# WKUP_CTRL_MMR0_CFG0 register map
Vendor: Texas Instruments
Peripheral module from a debugger description file (folder J7VCL).
Registers are 32-bit, access per field, reset 0x0 unless marked. A register's access mark holds for its fields unless they carry their own. Offsets are as the file gives them; lines under a group give offsets from that group; [hi:lo] are bit positions; {n}, {i} and the like mark numbered series; 'fields as' and 'values as' point back to an identical list; <NAME> marks a mode.

## WKUP_CTRL_MMR0_CFG0 (part 1 of 2)
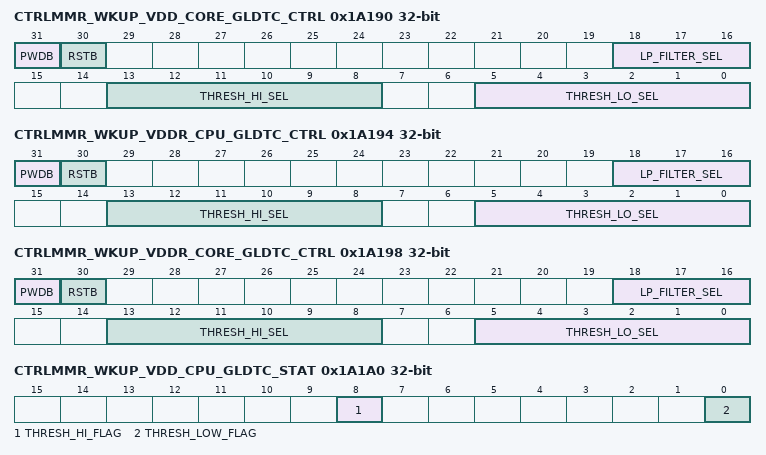
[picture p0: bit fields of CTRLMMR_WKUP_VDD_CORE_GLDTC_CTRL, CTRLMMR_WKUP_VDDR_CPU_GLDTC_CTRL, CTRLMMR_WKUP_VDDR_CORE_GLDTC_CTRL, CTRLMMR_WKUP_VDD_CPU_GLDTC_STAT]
0x1A190 CTRLMMR_WKUP_VDD_CORE_GLDTC_CTRL (reset mask 0xFFF8C0C0)
  [31] PWDB rw — Power down - active low.
  [30] RSTB rw — Reset - active low. To ensure proper operation, rstb must be not be de-asserted for at least 100 ns after power-up (pwdb de-asserted). Additionally, rstb must be toggled low at least 200 ns after any change in threshold or low-pass filter settings to prevent abnormal trigger events.
  [18:16] LP_FILTER_SEL rw — Selects the glitch detect low-pass filter bandwidth 0h - 150 kHz 1h - 125 kHz 2h - 100 kHz 3h - 80 kHz 4h - 60 kHz 5h - 45 kHz 6h - 30 kHz 7h - 15 kHz
  [13:8] THRESH_HI_SEL rw — Selects the high voltage glitch threshold as a percentage of the monitored voltage 0h - 93.5% of VDD 1h - 94.0% of VDD 2h - 94.5% of VDD 3h - 95.0% of VDD 4h - 95.5% of VDD 5h - 96.0% of VDD 6h - 96.5% of VDD 7h - 97.0% of VDD 8h - 97.5% of VDD 9h - 98.0% of VDD Ah - 98.5% of VDD Bh - 99.0% of VDD Ch - 99.5% of VDD Dh - 100.0% of VDD Eh - 100.5% of VDD Fh - 101.0% of VDD 10h - 101.5% of VDD 11h - 102.0% of VDD 12h - 102.5% of VDD 13h - 103.0% of VDD 14h - 103.5% of VDD 15h - 104.0% of VDD 16h - 104.5% of VDD 17h - 105.0% of VDD 18h - 105.5% of VDD 19h - 106.0% of VDD 1Ah - 106.5% of VDD 1Bh - 107.0% of VDD 1Ch - 107.5% of VDD 1Dh - 108.0% of VDD 1Eh - 108.5% of VDD 1Fh - 109.0% of VDD 20h - 109.5% of VDD 21h - 110.0% of VDD 22h - 111.0% of VDD 23h - 112.0% of VDD 24h - 113.0% of VDD 25h - 114.0% of VDD 26h - 115.0% of VDD 27h - 116.0% of VDD 28h - 117.0% of VDD 29h - 118.0% of VDD 2Ah - 119.0% of VDD 2Bh - 120.0% of VDD 2Ch - 121.0% of VDD 2Dh - 122.0% of VDD 2Eh - 123.0% of VDD 2Fh - 124.0% of VDD 30h - 125.0% of VDD 31h - 126.0% of VDD 32h - 127.0% of VDD 33h - 128.0% of VDD 34h - 129.0% of VDD 35h - 130.0% of VDD 36h - 131.0% of VDD 37h - 132.0% of VDD 38h - 133.0% of VDD 39h - 134.0% of VDD 3Ah - 135.0% of VDD 3Bh - 136.0% of VDD 3Ch - 137.0% of VDD 3Dh - 138.0% of VDD 3Eh - 139.0% of VDD 3Fh - 140.0% of VDD
  [5:0] THRESH_LO_SEL rw — Selects the low voltage glitch threshold as a percentage of the monitored voltage 0h - 106.5% of VDD 1h - 106.0% of VDD 2h - 105.5% of VDD 3h - 105.0% of VDD 4h - 104.5% of VDD 5h - 104.0% of VDD 6h - 103.5% of VDD 7h - 103.0% of VDD 8h - 102.5% of VDD 9h - 102.0% of VDD Ah - 101.5% of VDD Bh - 101.0% of VDD Ch - 100.5% of VDD Dh - 100.0% of VDD Eh - 99.5% of VDD Fh - 99.0% of VDD 10h - 98.5% of VDD 11h - 98.0% of VDD 12h - 97.5% of VDD 13h - 97.0% of VDD 14h - 96.5% of VDD 15h - 96.0% of VDD 16h - 95.5% of VDD 17h - 95.0% of VDD 18h - 94.5% of VDD 19h - 94.0% of VDD 1Ah - 93.5% of VDD 1Bh - 93.0% of VDD 1Ch - 92.5% of VDD 1Dh - 92.0% of VDD 1Eh - 91.5% of VDD 1Fh - 91.0% of VDD 20h - 90.5% of VDD 21h - 90.0% of VDD 22h - 89.0% of VDD 23h - 88.0% of VDD 24h - 87.0% of VDD 25h - 86.0% of VDD 26h - 85.0% of VDD 27h - 84.0% of VDD 28h - 83.0% of VDD 29h - 82.0% of VDD 2Ah - 81.0% of VDD 2Bh - 80.0% of VDD 2Ch - 79.0% of VDD 2Dh - 78.0% of VDD 2Eh - 77.0% of VDD 2Fh - 76.0% of VDD 30h - 75.0% of VDD 31h - 74.0% of VDD 32h - 73.0% of VDD 33h - 72.0% of VDD 34h - 71.0% of VDD 35h - 70.0% of VDD 36h - 69.0% of VDD 37h - 68.0% of VDD 38h - 67.0% of VDD 39h - 66.0% of VDD 3Ah - 65.0% of VDD 3Bh - 64.0% of VDD 3Ch - 63.0% of VDD 3Dh - 62.0% of VDD 3Eh - 61.0% of VDD 3Fh - 60.0% of VDD
0x1A194 CTRLMMR_WKUP_VDDR_CPU_GLDTC_CTRL (reset mask 0xFFF8C0C0)
  fields as CTRLMMR_WKUP_VDD_CORE_GLDTC_CTRL
0x1A198 CTRLMMR_WKUP_VDDR_CORE_GLDTC_CTRL (reset mask 0xFFF8C0C0)
  fields as CTRLMMR_WKUP_VDD_CORE_GLDTC_CTRL
0x1A1A0 CTRLMMR_WKUP_VDD_CPU_GLDTC_STAT ro (reset mask 0xFFFFFEFE)
  [8] THRESH_HI_FLAG — High voltage flag. This flag is cleared by clearing the VDD_CPU_GLDTC_CTRL_rstb bit.
  [0] THRESH_LOW_FLAG — Low voltage flag. This flag is cleared by clearing the VDD_CPU_GLDTC_CTRL_rstb bit.
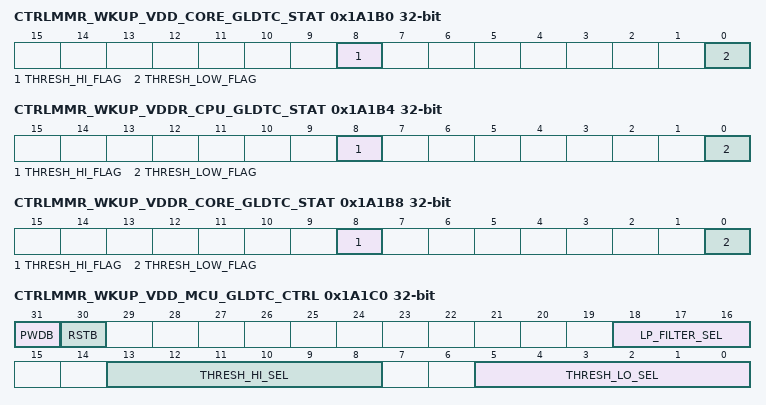
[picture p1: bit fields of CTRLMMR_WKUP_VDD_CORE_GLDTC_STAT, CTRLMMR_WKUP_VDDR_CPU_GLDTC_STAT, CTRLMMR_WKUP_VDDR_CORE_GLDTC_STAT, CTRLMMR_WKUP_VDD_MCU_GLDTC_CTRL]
0x1A1B0 CTRLMMR_WKUP_VDD_CORE_GLDTC_STAT ro (reset mask 0xFFFFFEFE)
  [8] THRESH_HI_FLAG — High voltage flag. This flag is cleared by clearing the VDD_CORE_GLDTC_CTRL_rstb bit.
  [0] THRESH_LOW_FLAG — Low voltage flag. This flag is cleared by clearing the VDD_CORE_GLDTC_CTRL_rstb bit.
0x1A1B4 CTRLMMR_WKUP_VDDR_CPU_GLDTC_STAT ro (reset mask 0xFFFFFEFE)
  [8] THRESH_HI_FLAG — High voltage flag. This flag is cleared by clearing the VDDR_CPU_GLDTC_CTRL_rstb bit.
  [0] THRESH_LOW_FLAG — Low voltage flag. This flag is cleared by clearing the VDDR_CPU_GLDTC_CTRL_rstb bit.
0x1A1B8 CTRLMMR_WKUP_VDDR_CORE_GLDTC_STAT ro (reset mask 0xFFFFFEFE)
  [8] THRESH_HI_FLAG — High voltage flag. This flag is cleared by clearing the VDDR_CORE_GLDTC_CTRL_rstb bit.
  [0] THRESH_LOW_FLAG — Low voltage flag. This flag is cleared by clearing the VDDR_CORE_GLDTC_CTRL_rstb bit.
0x1A1C0 CTRLMMR_WKUP_VDD_MCU_GLDTC_CTRL (reset mask 0xFFF8C0C0)
  fields as CTRLMMR_WKUP_VDD_CORE_GLDTC_CTRL
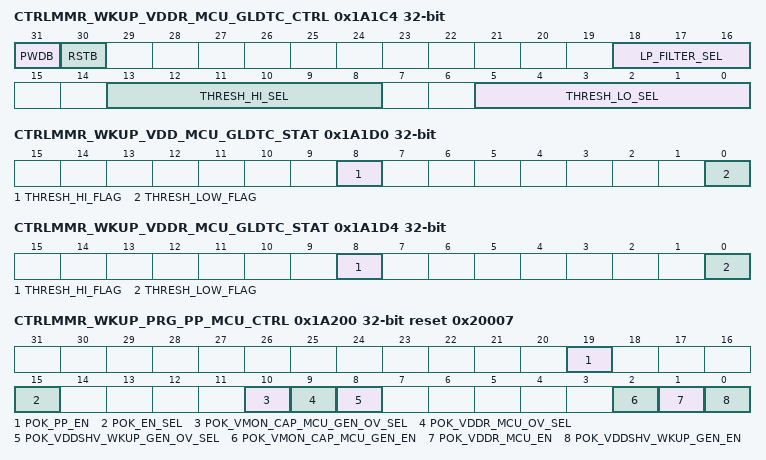
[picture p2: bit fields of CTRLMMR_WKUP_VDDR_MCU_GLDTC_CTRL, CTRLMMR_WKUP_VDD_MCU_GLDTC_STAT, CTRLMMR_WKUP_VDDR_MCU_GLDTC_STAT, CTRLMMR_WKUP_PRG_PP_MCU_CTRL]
0x1A1C4 CTRLMMR_WKUP_VDDR_MCU_GLDTC_CTRL (reset mask 0xFFF8C0C0)
  fields as CTRLMMR_WKUP_VDD_CORE_GLDTC_CTRL
0x1A1D0 CTRLMMR_WKUP_VDD_MCU_GLDTC_STAT ro (reset mask 0xFFFFFEFE)
  [8] THRESH_HI_FLAG — High voltage flag. This flag is cleared by clearing the VDD_MCU_GLDTC_CTRL_rstb bit.
  [0] THRESH_LOW_FLAG — Low voltage flag. This flag is cleared by clearing the VDD_MCU_GLDTC_CTRL_rstb bit.
0x1A1D4 CTRLMMR_WKUP_VDDR_MCU_GLDTC_STAT ro (reset mask 0xFFFFFEFE)
  [8] THRESH_HI_FLAG — High voltage flag. This flag is cleared by clearing the VDDR_MCU_GLDTC_CTRL_rstb bit.
  [0] THRESH_LOW_FLAG — Low voltage flag. This flag is cleared by clearing the VDDR_MCU_GLDTC_CTRL_rstb bit.
0x1A200 CTRLMMR_WKUP_PRG_PP_MCU_CTRL reset 0x20007
  [19] POK_PP_EN rw — POK ping-pong enable. When set, enables automatic switching between undervoltage and overvoltage detection on VDDSHV_WKUP_GENERAL, VDDR_MCU and VMON_CAP_MCU_GENERAL POKs. This bit has no effect if the POK's ov_sel bit = 1.
  [15] POK_EN_SEL rw — Select POK enable source
  [10] POK_VMON_CAP_MCU_GEN_OV_SEL rw — Force VMON_CAP_MCU_GENERAL POK overvoltage detection. If this bit is 0 and pok_pp_en bit is also 0 then only undervoltage detection is enabled.
  [9] POK_VDDR_MCU_OV_SEL rw — Force VDDR_MCU POK overvoltage detection. If this bit is 0 and pok_pp_en bit is also 0 then only undervoltage detection is enabled.
  [8] POK_VDDSHV_WKUP_GEN_OV_SEL rw — Force VDDSHV_WKUP_GENERAL POK overvoltage detection. If this bit is 0 and pok_pp_en bit is also 0 then only undervoltage detection is enabled.
  [2] POK_VMON_CAP_MCU_GEN_EN rw — Enable VMON_CAP_MCU_GENERAL POK detection
  [1] POK_VDDR_MCU_EN rw — Enable VDDR_MCU POK detection
  [0] POK_VDDSHV_WKUP_GEN_EN rw — Enable VDDSHV_WKUP_GENERAL POK detection
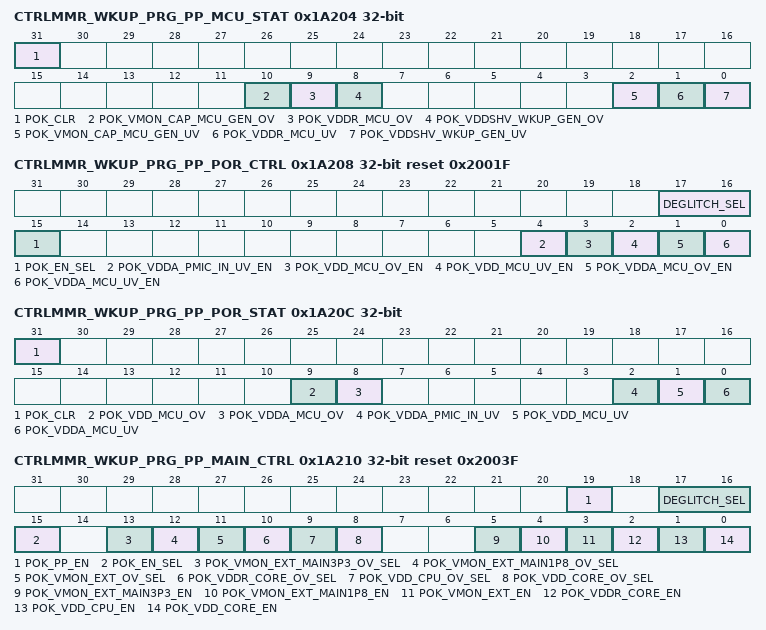
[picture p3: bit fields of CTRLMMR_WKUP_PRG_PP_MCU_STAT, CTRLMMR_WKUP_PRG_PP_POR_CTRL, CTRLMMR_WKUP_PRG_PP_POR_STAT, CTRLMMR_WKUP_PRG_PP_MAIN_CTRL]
0x1A204 CTRLMMR_WKUP_PRG_PP_MCU_STAT (reset mask 0xFFFFF8F8)
  [31] POK_CLR rw — When set, resets pgood sticky bits for VDDSHV_WKUP_GENERAL, VDDR_MCU, and VMON_CAP_MCU_GENERAL voltage POK detection.
  [10] POK_VMON_CAP_MCU_GEN_OV ro — VMON_CAP_MCU_GENERAL overvoltage POK
  [9] POK_VDDR_MCU_OV ro — VDDR_MCU overvoltage POK
  [8] POK_VDDSHV_WKUP_GEN_OV ro — VDDSHV_WKUP_GENERAL overvoltage POK
  [2] POK_VMON_CAP_MCU_GEN_UV ro — VMON_CAP_MCU_GENERAL undervoltage POK
  [1] POK_VDDR_MCU_UV ro — VDDR_MCU undervoltage POK
  [0] POK_VDDSHV_WKUP_GEN_UV ro — VDDSHV_WKUP_GENERAL undervoltage POK
0x1A208 CTRLMMR_WKUP_PRG_PP_POR_CTRL reset 0x2001F
  [17:16] DEGLITCH_SEL rw — Deglitch period for PRG_PP_POR POKs 0h - 5 us 1h - 10 us 2h - 15 us 3h - 20 us
  [15] POK_EN_SEL rw — Select POK enable source
  [4] POK_VDDA_PMIC_IN_UV_EN rw — Enable VDDA_PMIC_IN undervoltage POK detection
  [3] POK_VDD_MCU_OV_EN rw — Enable VDD_MCU overvoltage POK detection
  [2] POK_VDD_MCU_UV_EN rw — Enable VDD_MCU undervoltage POK detection
  [1] POK_VDDA_MCU_OV_EN rw — Enable 1.8V VDDA_MCU overvoltage POK detection
  [0] POK_VDDA_MCU_UV_EN rw — Enable 1.8V VDDA_MCU undervoltage POK detection
0x1A20C CTRLMMR_WKUP_PRG_PP_POR_STAT (reset mask 0xFFFFFCF8)
  [31] POK_CLR rw — When set, resets pgood sticky bits for VDDA_MCU, VDD_MCU, and VDDA_PMIC_IN voltage POK detection.
  [9] POK_VDD_MCU_OV ro — VDD_MCU overvoltage POK detection
  [8] POK_VDDA_MCU_OV ro — 1.8V VDDA_MCU overvoltage POK detection
  [2] POK_VDDA_PMIC_IN_UV ro — VDDA_PMIC_IN undervoltage POK detection
  [1] POK_VDD_MCU_UV ro — VDD_MCU undervoltage POK detection
  [0] POK_VDDA_MCU_UV ro — 1.8V VDDA_MCU undervoltage POK detection
0x1A210 CTRLMMR_WKUP_PRG_PP_MAIN_CTRL reset 0x2003F
  [19] POK_PP_EN rw — POK ping-pong enable. When set, enables automatic switching between undervoltage and overvoltage detection on VDD_CORE, VDD_CPU, VDDR_CORE, VMON_EXT, VMON_EXT_MAIN1P8 and VMON_EXT_MAIN3P3. This bit has no effect if the POK's ov_sel bit = 1.
  [17:16] DEGLITCH_SEL rw — Deglitch period for PRG_PP_MAIN POKs 0h - 5 us 1h - 10 us 2h - 15 us 3h - 20 us
  [15] POK_EN_SEL rw — Select POK enable source
  [13] POK_VMON_EXT_MAIN3P3_OV_SEL rw — Force VMON_EXT_MAIN 3.3V POK overvoltage detection. If this bit is 0 and pok_pp_en bit is also 0 then only undervoltage detection is enabled.
  [12] POK_VMON_EXT_MAIN1P8_OV_SEL rw — Force VMON_EXT_MAIN 1.8V POK overvoltage detection. If this bit is 0 and pok_pp_en bit is also 0 then only undervoltage detection is enabled.
  [11] POK_VMON_EXT_OV_SEL rw — Force VMON_EXT POK overvoltage detection. If this bit is 0 and pok_pp_en bit is also 0 then only undervoltage detection is enabled.
  [10] POK_VDDR_CORE_OV_SEL rw — Force VDDR_CORE POK overvoltage detection. If this bit is 0 and pok_pp_en bit is also 0 then only undervoltage detection is enabled.
  [9] POK_VDD_CPU_OV_SEL rw — Force VDD_CPU POK overvoltage detection. If this bit is 0 and pok_pp_en bit is also 0 then only undervoltage detection is enabled.
  [8] POK_VDD_CORE_OV_SEL rw — Force VDD_CORE POK overvoltage detection. If this bit is 0 and pok_pp_en bit is also 0 then only undervoltage detection is enabled.
  [5] POK_VMON_EXT_MAIN3P3_EN rw — Enable VMON_EXT_MAIN 3.3V POK detection
  [4] POK_VMON_EXT_MAIN1P8_EN rw — Enable VMON_EXT_MAIN 1.8V POK detection
  [3] POK_VMON_EXT_EN rw — Enable VMON_EXT POK detection
  [2] POK_VDDR_CORE_EN rw — Enable VDDR_CORE POK detection
  [1] POK_VDD_CPU_EN rw — Enable VDD_CPU POK detection
  [0] POK_VDD_CORE_EN rw — Enable VDD_CORE POK detection
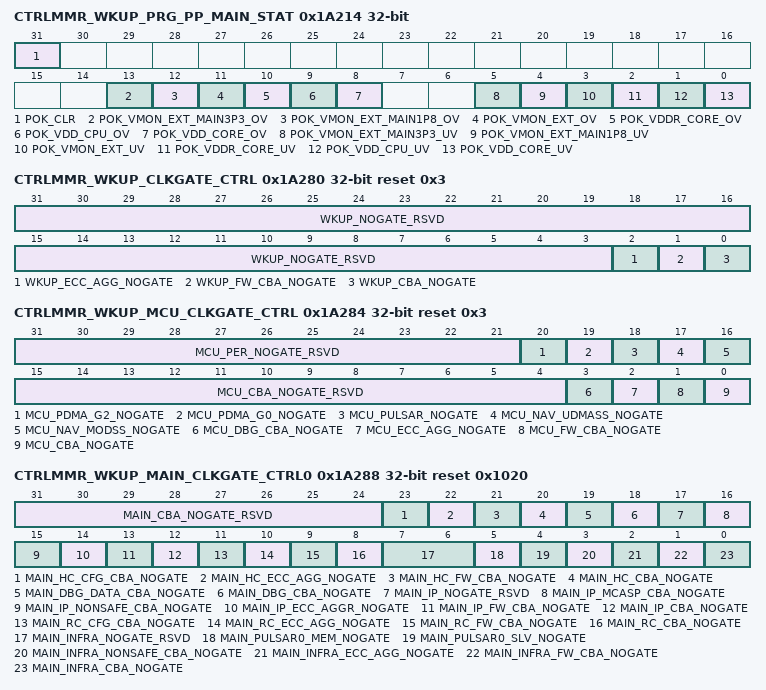
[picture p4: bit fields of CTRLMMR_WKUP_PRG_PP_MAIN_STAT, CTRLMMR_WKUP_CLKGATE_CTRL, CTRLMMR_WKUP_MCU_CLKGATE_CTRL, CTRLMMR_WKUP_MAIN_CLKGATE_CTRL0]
0x1A214 CTRLMMR_WKUP_PRG_PP_MAIN_STAT (reset mask 0xFFFFC0C0)
  [31] POK_CLR rw — When set, resets pgood sticky bits for V DD_CORE, VDD_CPU, VDDR_CORE, VMON_EXT, VMON_EXT_MAIN1P8, and VMON_EXT_MAIN3P3 voltage POK detection.
  [13] POK_VMON_EXT_MAIN3P3_OV ro — VMON_EXT_MAIN 3.3V overvoltage POK
  [12] POK_VMON_EXT_MAIN1P8_OV ro — VMON_EXT_MAIN 1.8V overvoltage POK
  [11] POK_VMON_EXT_OV ro — VMON_EXT overvoltage POK
  [10] POK_VDDR_CORE_OV ro — VDDR_CORE overvoltage POK
  [9] POK_VDD_CPU_OV ro — VDD_CPU overvoltage POK
  [8] POK_VDD_CORE_OV ro — VDD_CORE overvoltage POK
  [5] POK_VMON_EXT_MAIN3P3_UV ro — VMON_EXT_MAIN 3.3V undervoltage POK
  [4] POK_VMON_EXT_MAIN1P8_UV ro — VMON_EXT_MAIN 1.8V undervoltage POK
  [3] POK_VMON_EXT_UV ro — VMON_EXT undervoltage POK
  [2] POK_VDDR_CORE_UV ro — VDDR_CORE undervoltage POK
  [1] POK_VDD_CPU_UV ro — VDD_CPU undervoltage POK
  [0] POK_VDD_CORE_UV ro — VDD_CORE undervoltage POK
0x1A280 CTRLMMR_WKUP_CLKGATE_CTRL rw reset 0x3 (reset mask 0x3)
  [31:3] WKUP_NOGATE_RSVD — WKUP reserved clock gate disable. These bits should remain unchanged (written only with their default value) to maintain compatibility with future devices.
  [2] WKUP_ECC_AGG_NOGATE — WKUP ECC Aggregator clock gate disable
  [1] WKUP_FW_CBA_NOGATE — WKUP domain Firewall bus (wkup_fw_cbass) clock gate disable
  [0] WKUP_CBA_NOGATE — WKUP domain Data bus (wkup_cbass) clock gate disable
0x1A284 CTRLMMR_WKUP_MCU_CLKGATE_CTRL rw reset 0x3 (reset mask 0x3)
  [31:21] MCU_PER_NOGATE_RSVD — MCU reserved clock gate disable. These bits should remain unchanged (written only with their default value) to maintain compatibility with future devices.
  [20] MCU_PDMA_G2_NOGATE — MCU domain MCAN1/USART0 PDMA clock gate disable.
  [19] MCU_PDMA_G0_NOGATE — MCU domain MCAN0/SPI0 PDMA clock gate disable.
  [18] MCU_PULSAR_NOGATE — MCU domain Pulsar clock gate disable.
  [17] MCU_NAV_UDMASS_NOGATE — MCU NavSS UDMA interface clock gate disable.
  [16] MCU_NAV_MODSS_NOGATE — MCU NavSS MODSS interface clock gate disable.
  [15:4] MCU_CBA_NOGATE_RSVD — MCU reserved clock gate disable. These bits should remain unchanged (written only with their default value) to maintain compatibility with future devices.
  [3] MCU_DBG_CBA_NOGATE — MCU domain Debug bus (mcu_dbg_cbass) clock gate disable.
  [2] MCU_ECC_AGG_NOGATE — MCU ECC Aggregator clock gate disable
  [1] MCU_FW_CBA_NOGATE — MCU domain Firewall bus (mcu_fw_cbass) clock gate disable.
  [0] MCU_CBA_NOGATE — MCU domain Data bus (mcu_cbass) clock gate disable.
0x1A288 CTRLMMR_WKUP_MAIN_CLKGATE_CTRL0 rw reset 0x1020 (reset mask 0x1020)
  [31:24] MAIN_CBA_NOGATE_RSVD — MAIN CBA reserved clock gate disable. These bits should remain unchanged (written only with their default value) to maintain compatibility with future devices.
  [23] MAIN_HC_CFG_CBA_NOGATE — MAIN domain HC Configuration bus (hc_cfg_cbass_0) clock gate disable.
  [22] MAIN_HC_ECC_AGG_NOGATE — MAIN domain HC ECC aggregator (nogate) clock gate disable.
  [21] MAIN_HC_FW_CBA_NOGATE — MAIN domain HC Firewall bus (main_hc2_fw_cbass_0) clock gate disable.
  [20] MAIN_HC_CBA_NOGATE — MAIN domain HC Data bus (hc2_cbass_0) clock gate disable.
  [19] MAIN_DBG_DATA_CBA_NOGATE — MAIN domain Debug Data bus (debug_cbass) clock gate disable.
  [18] MAIN_DBG_CBA_NOGATE — MAIN domain Debug bus (debug_cbass_wrap_main_0) clock gate disable.
  [17] MAIN_IP_NOGATE_RSVD — MAIN Interface Peripheral reserved clock gate disable. These bits should remain unchanged (written only with their default value) to maintain compatibility with future devices.
  [16] MAIN_IP_MCASP_CBA_NOGATE — MAIN domain Interface Peripheral McASP IP bus (ipphy_mcasp_g0) clock gate disable.
  [15] MAIN_IP_NONSAFE_CBA_NOGATE — MAIN domain Interface Peripheral nonsafety IP bus (ipphy_cbass_0) clock gate disable.
  [14] MAIN_IP_ECC_AGGR_NOGATE — MAIN domain Interface Peripheral ECC aggregator (main_spi0_g0_main_0_ecc_aggr_main_0) clock gate disable.
  [13] MAIN_IP_FW_CBA_NOGATE — MAIN domain Interface Peripheral Firewall bus (ipphy_cbass_main_fw_cbass) clock gate disable.
  [12] MAIN_IP_CBA_NOGATE — MAIN domain Interface Peripheral bus (ipphy_safe_cbass_0) clock gate disable.
  [11] MAIN_RC_CFG_CBA_NOGATE — MAIN domain RC Configuration bus (rc_cfg_cbass_0) clock gate disable.
  [10] MAIN_RC_ECC_AGG_NOGATE — MAIN domain RC ECC aggregator (main_rc_ecc_aggr_main_0) clock gate disable.
  [9] MAIN_RC_FW_CBA_NOGATE — MAIN domain RC Firewall bus (rc_cbass_main_fw_cbass) clock gate disable.
  [8] MAIN_RC_CBA_NOGATE — MAIN domain RC Data bus (rc_cbass_0) clock gate disable.
  [7:6] MAIN_INFRA_NOGATE_RSVD — MAIN Infrastructure reserved clock gate disable. These bits should remain unchanged (written only with their default value) to maintain compatibility with future devices.
  [5] MAIN_PULSAR0_MEM_NOGATE — MAIN domain Pulsar memory bus (pulsar0_mem_cbass) clock gate disable.
  [4] MAIN_PULSAR0_SLV_NOGATE — MAIN domain Pulsar slave bus (pulsar0_slv_cbass) clock gate disable.
  [3] MAIN_INFRA_NONSAFE_CBA_NOGATE — MAIN domain Infrastructure non-safety IP bus (main_infra_non_safe_cbass) clock gate disable.
  [2] MAIN_INFRA_ECC_AGG_NOGATE — MAIN domain Infrastructure ECC aggregator (main_infra_ecc_aggr) clock gate disable.
  [1] MAIN_INFRA_FW_CBA_NOGATE — MAIN domain Infrastructure Firewall bus (main_infra_fw_cbass) clock gate disable.
  [0] MAIN_INFRA_CBA_NOGATE — MAIN domain Infrastructure bus (main_infra_cbass) clock gate disable.
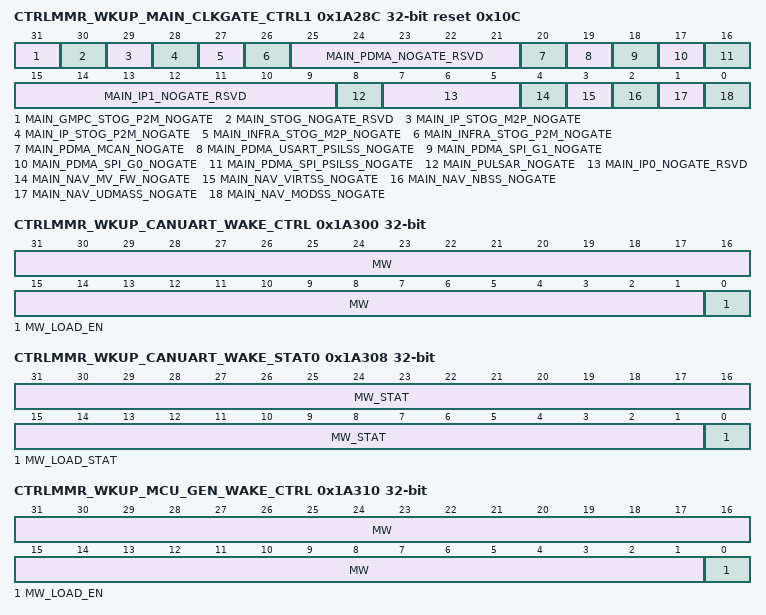
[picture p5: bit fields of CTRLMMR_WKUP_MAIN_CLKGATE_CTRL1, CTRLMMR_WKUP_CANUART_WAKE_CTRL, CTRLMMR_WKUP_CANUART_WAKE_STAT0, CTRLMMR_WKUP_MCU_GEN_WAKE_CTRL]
0x1A28C CTRLMMR_WKUP_MAIN_CLKGATE_CTRL1 rw reset 0x10C (reset mask 0x10C)
  [31] MAIN_GMPC_STOG_P2M_NOGATE — MAIN domain GPMC Slave Timeout Gasket output (rc_to_gpmc_stog_p2m_pwr_dis) clock gate disable.
  [30] MAIN_STOG_NOGATE_RSVD — MAIN STOG clock gate disable. These bits should remain unchanged (written only with their default value) to maintain compatibility with future devices.
  [29] MAIN_IP_STOG_M2P_NOGATE — MAIN domain IP Slave Timeout Gasket output (ipphy_to_ipphy_stog_p2m_pwr_dis) clock gate disable.
  [28] MAIN_IP_STOG_P2M_NOGATE — MAIN domain IP Slave Timeout Gasket input (ipphy_to_ipphy_stog_p2m_pwr_dis) clock gate disable.
  [27] MAIN_INFRA_STOG_M2P_NOGATE — MAIN domain Infrastructure Slave Timeout Gasket output (main_infra_0_mst_stog_p2m_pwr_dis) clock gate disable.
  [26] MAIN_INFRA_STOG_P2M_NOGATE — MAIN domain Infrastructure Slave Timeout Gasket input (main_infra_0_mst_stog_p2m_pwr_dis) clock gate disable.
  [25:21] MAIN_PDMA_NOGATE_RSVD — MAIN PDMA clock gate disable. These bits should remain unchanged (written only with their default value) to maintain compatibility with future devices.
  [20] MAIN_PDMA_MCAN_NOGATE — MAIN domain PDMA MCAN clock gate disable.
  [19] MAIN_PDMA_USART_PSILSS_NOGATE — MAIN domain PDMA USART PSILSS clock gate disable.
  [18] MAIN_PDMA_SPI_G1_NOGATE — MAIN domain PDMA SPI_G1 clock gate disable.
  [17] MAIN_PDMA_SPI_G0_NOGATE — MAIN domain PDMA SPI_G0 clock gate disable.
  [16] MAIN_PDMA_SPI_PSILSS_NOGATE — MAIN domain PDMA SPI PSILSS clock gate disable.
  [15:9] MAIN_IP1_NOGATE_RSVD — MAIN IP reserved clock gate disable. These bits should remain unchanged (written only with their default value) to maintain compatibility with future devices.
  [8] MAIN_PULSAR_NOGATE — MAIN domain Pulsar clock gate disable.
  [7:5] MAIN_IP0_NOGATE_RSVD — MAIN IP reserved clock gate disable. These bits should remain unchanged (written only with their default value) to maintain compatibility with future devices.
  [4] MAIN_NAV_MV_FW_NOGATE — MAIN NavSS Mod/Virt Firewall interface clock gate disable.
  [3] MAIN_NAV_VIRTSS_NOGATE — MAIN NavSS VIRTSS interface clock gate disable.
  [2] MAIN_NAV_NBSS_NOGATE — MAIN NavSS NB interface clock gate disable.
  [1] MAIN_NAV_UDMASS_NOGATE — Main NavSS UDMA interface clock gate disable.
  [0] MAIN_NAV_MODSS_NOGATE — MAIN NavSS MODSS interface clock gate disable.
0x1A300 CTRLMMR_WKUP_CANUART_WAKE_CTRL rw
  [31:1] MW — CANUART IO magic word.
  [0] MW_LOAD_EN — Magic word load enable
0x1A308 CTRLMMR_WKUP_CANUART_WAKE_STAT0 ro reset not defined
  [31:1] MW_STAT — CANUART magic word status
  [0] MW_LOAD_STAT — Magic word load status.
0x1A30C CTRLMMR_WKUP_CANUART_WAKE_STAT1 ro (reset mask 0xFFFFFFFE)
  [0] CANUART_IO_MODE — Indicates if CANUART IO wakeup mode is enabled.
0x1A310 CTRLMMR_WKUP_MCU_GEN_WAKE_CTRL rw
  [31:1] MW — MCU_GENERAL IO magic word.
  [0] MW_LOAD_EN — Magic word load enable
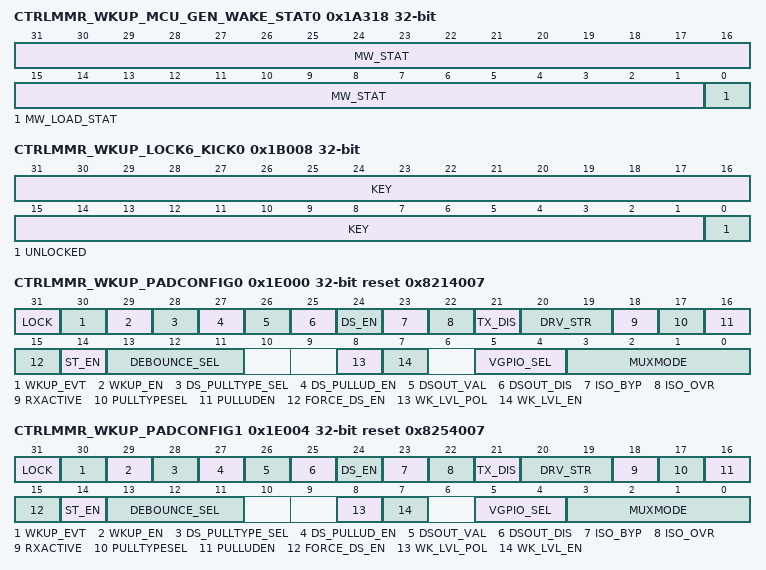
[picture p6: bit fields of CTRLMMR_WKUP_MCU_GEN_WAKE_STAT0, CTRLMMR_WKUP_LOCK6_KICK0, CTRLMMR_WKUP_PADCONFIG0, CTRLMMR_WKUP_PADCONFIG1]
0x1A318 CTRLMMR_WKUP_MCU_GEN_WAKE_STAT0 ro reset not defined
  [31:1] MW_STAT — MCU_GENERAL magic word status
  [0] MW_LOAD_STAT — Magic word load status.
0x1A31C CTRLMMR_WKUP_MCU_GEN_WAKE_STAT1 ro (reset mask 0xFFFFFFFE)
  [0] MCU_GEN_IO_MODE — Indicates if MCU_GENERAL IO wakeup mode is enabled.
0x1B008 CTRLMMR_WKUP_LOCK6_KICK0
  [31:1] KEY rw — Write the kick0 unlock value followed by the kick1 unlock value to unlock the write-protected Partition6 registers
  [0] UNLOCKED ro — Unlock status.
0x1B00C CTRLMMR_WKUP_LOCK6_KICK1 rw
  [31:0] KEY — Write the kick1 unlock value after the kick0 unlock value to unlock the write-protected Partition6 registers
{0x1B100+4i} CTRLMMR_WKUP_P6_CLAIM{i} rw (i=0..6)
  [31:0] PROXY1_CLAIMED — Proxy1 register claim bit
0x1E000 CTRLMMR_WKUP_PADCONFIG0 reset 0x8214007
  [31] LOCK rw
  [30] WKUP_EVT ro — Wakeup event status
  [29] WKUP_EN rw — Wakeup enable
  [28] DS_PULLTYPE_SEL rw — Deep Sleep pull-up/down selection
  [27] DS_PULLUD_EN rw — Deep Sleep pull-up/down enable (active low)
  [26] DSOUT_VAL rw — Deep Sleep output value
  [25] DSOUT_DIS rw — Deep Sleep output enable
  [24] DS_EN rw — Deep Sleep override control
  [23] ISO_BYP rw — Isolation Bypass
  [22] ISO_OVR rw — Isolation Override
  [21] TX_DIS rw — Driver Disable
  [20:19] DRV_STR rw — Drive Strength Control . Selects the drive strength value for LVCMOS pins. (Does not apply to other pin types)
  [18] RXACTIVE rw — Input enable for the Pad
  [17] PULLTYPESEL rw — Pad Pullup / Pulldown type selection
  [16] PULLUDEN rw — Pad Pullup / Pulldown enable. This is an active low signal.
  [15] FORCE_DS_EN rw — Enable pad Deep Sleep controls by overriding DMSC gating
  [14] ST_EN rw — Receiver Schmitt Trigger enable
  [13:11] DEBOUNCE_SEL rw — Selects the debounce period for the pad.
  [8] WK_LVL_POL rw — Level Sensitive Wakeup Polarity
  [7] WK_LVL_EN rw — Level Sensitive Wakeup Enable
  [5:4] VGPIO_SEL rw — Virtual WKUP_GPIO instance select. 0h - Implement GPIO in GPIO_WKUP_0 instance 1h - Implement GPIO in GPIO_WKUP_1 instance
  [3:0] MUXMODE rw — Pad functional signal mux selection 0h - Mux Mode 0 1h - Mux Mode 1 2h - Mux Mode 2 3h - Mux Mode 3 4h - Mux Mode 4 5h - Mux Mode 5 6h - Mux Mode 6 7h - Mux Mode 7 Fh - Mux Mode 15
0x1E004 CTRLMMR_WKUP_PADCONFIG1 reset 0x8254007
  fields as CTRLMMR_WKUP_PADCONFIG0
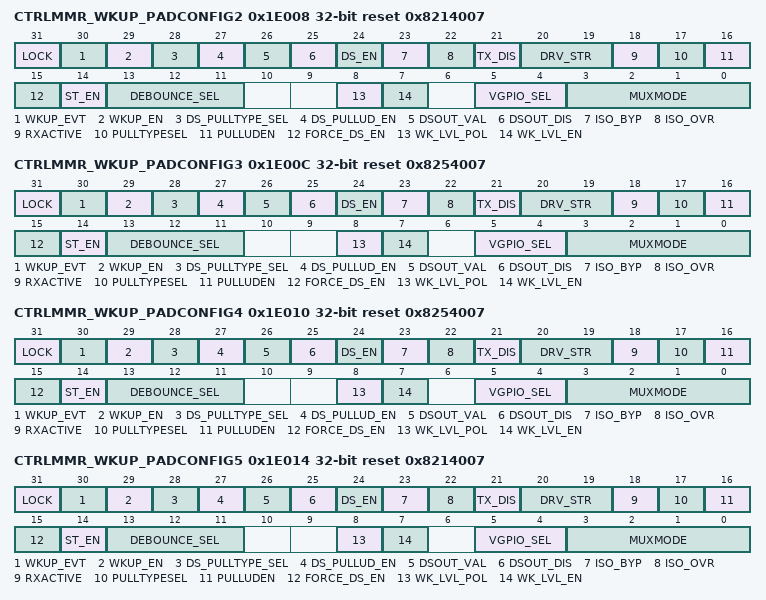
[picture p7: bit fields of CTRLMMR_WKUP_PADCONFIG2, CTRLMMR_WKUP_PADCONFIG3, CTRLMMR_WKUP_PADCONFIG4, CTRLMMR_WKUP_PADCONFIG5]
0x1E008 CTRLMMR_WKUP_PADCONFIG2 reset 0x8214007
  fields as CTRLMMR_WKUP_PADCONFIG0
0x1E00C CTRLMMR_WKUP_PADCONFIG3 reset 0x8254007
  fields as CTRLMMR_WKUP_PADCONFIG0
0x1E010 CTRLMMR_WKUP_PADCONFIG4 reset 0x8254007
  fields as CTRLMMR_WKUP_PADCONFIG0
0x1E014 CTRLMMR_WKUP_PADCONFIG5 reset 0x8214007
  fields as CTRLMMR_WKUP_PADCONFIG0
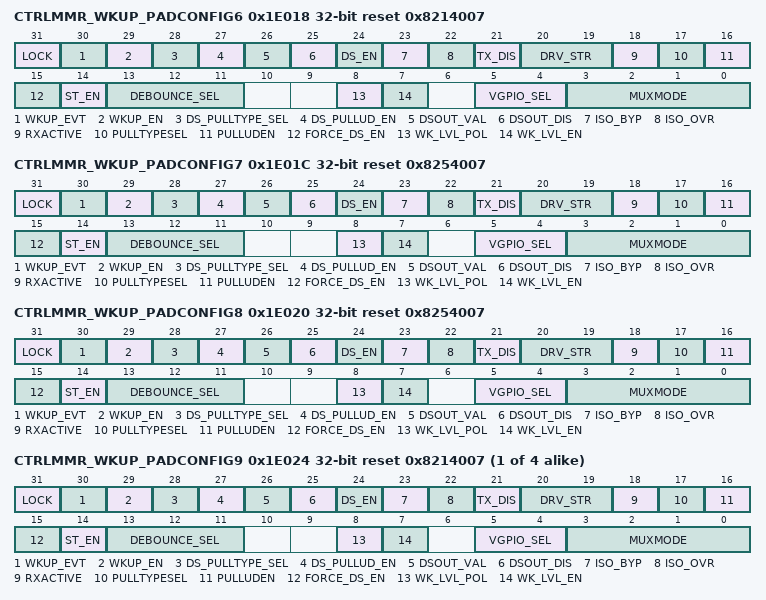
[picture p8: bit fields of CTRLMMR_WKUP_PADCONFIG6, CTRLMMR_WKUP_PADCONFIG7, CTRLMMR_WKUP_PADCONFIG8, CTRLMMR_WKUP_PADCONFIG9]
0x1E018 CTRLMMR_WKUP_PADCONFIG6 reset 0x8214007
  fields as CTRLMMR_WKUP_PADCONFIG0
0x1E01C CTRLMMR_WKUP_PADCONFIG7 reset 0x8254007
  fields as CTRLMMR_WKUP_PADCONFIG0
0x1E020 CTRLMMR_WKUP_PADCONFIG8 reset 0x8254007
  fields as CTRLMMR_WKUP_PADCONFIG0
{0x1E000+4i} CTRLMMR_WKUP_PADCONFIG{i} reset 0x8214007 (i=9..12)
  fields as CTRLMMR_WKUP_PADCONFIG0
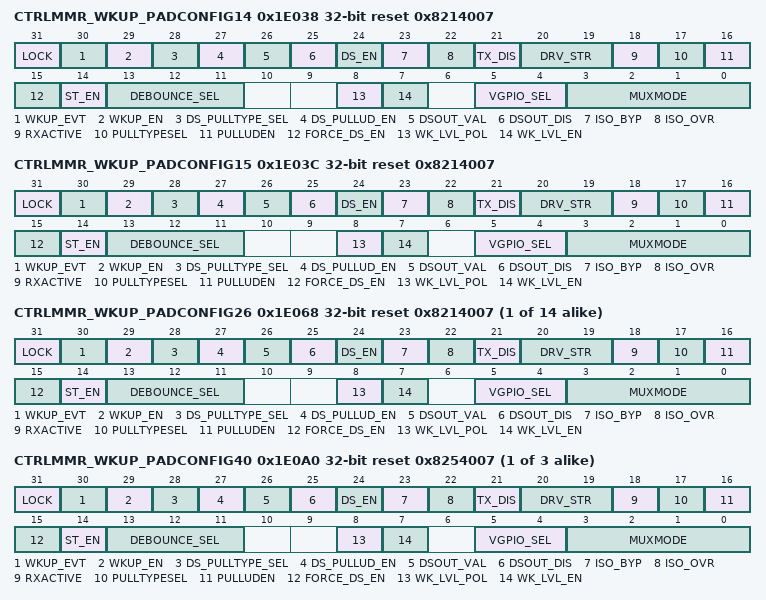
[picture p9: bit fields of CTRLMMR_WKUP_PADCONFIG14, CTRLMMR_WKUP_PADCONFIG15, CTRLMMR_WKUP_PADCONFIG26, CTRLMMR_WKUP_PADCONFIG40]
0x1E038 CTRLMMR_WKUP_PADCONFIG14 reset 0x8214007
  fields as CTRLMMR_WKUP_PADCONFIG0
0x1E03C CTRLMMR_WKUP_PADCONFIG15 reset 0x8214007
  fields as CTRLMMR_WKUP_PADCONFIG0
{0x1E000+4i} CTRLMMR_WKUP_PADCONFIG{i} reset 0x8214007 (i=26..39)
  fields as CTRLMMR_WKUP_PADCONFIG0
{0x1E000+4i} CTRLMMR_WKUP_PADCONFIG{i} reset 0x8254007 (i=40..42)
  fields as CTRLMMR_WKUP_PADCONFIG0
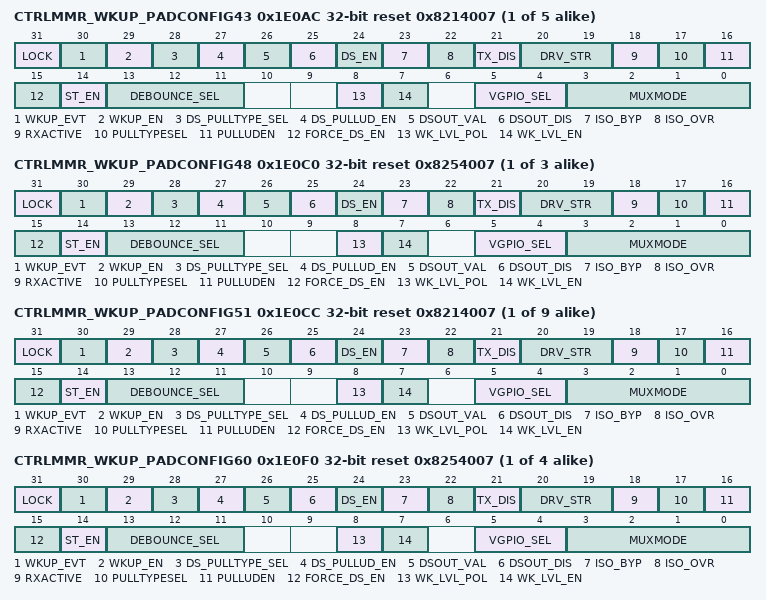
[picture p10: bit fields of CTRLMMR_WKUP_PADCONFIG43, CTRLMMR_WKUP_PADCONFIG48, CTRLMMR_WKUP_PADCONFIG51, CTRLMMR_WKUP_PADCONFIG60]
{0x1E000+4i} CTRLMMR_WKUP_PADCONFIG{i} reset 0x8214007 (i=43..47)
  fields as CTRLMMR_WKUP_PADCONFIG0
{0x1E000+4i} CTRLMMR_WKUP_PADCONFIG{i} reset 0x8254007 (i=48..50)
  fields as CTRLMMR_WKUP_PADCONFIG0
{0x1E000+4i} CTRLMMR_WKUP_PADCONFIG{i} reset 0x8214007 (i=51..59)
  fields as CTRLMMR_WKUP_PADCONFIG0
{0x1E000+4i} CTRLMMR_WKUP_PADCONFIG{i} reset 0x8254007 (i=60..63)
  fields as CTRLMMR_WKUP_PADCONFIG0
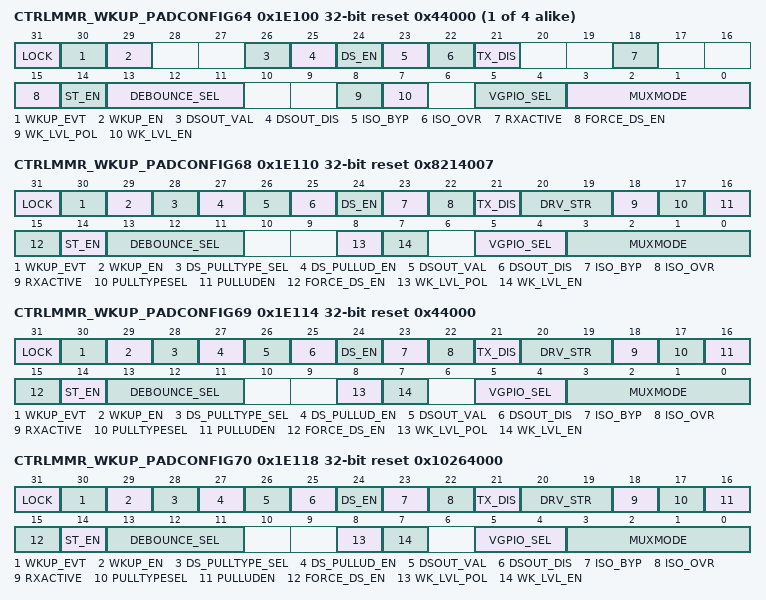
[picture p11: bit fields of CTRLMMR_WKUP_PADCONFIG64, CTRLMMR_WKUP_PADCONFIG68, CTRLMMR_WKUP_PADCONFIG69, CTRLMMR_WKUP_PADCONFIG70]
{0x1E000+4i} CTRLMMR_WKUP_PADCONFIG{i} reset 0x44000 (i=64..67)
  [31] LOCK rw
  [30] WKUP_EVT ro — Wakeup event status
  [29] WKUP_EN rw — Wakeup enable
  [26] DSOUT_VAL rw — Deep Sleep output value
  [25] DSOUT_DIS rw — Deep Sleep output enable
  [24] DS_EN rw — Deep Sleep override control
  [23] ISO_BYP rw — Isolation Bypass
  [22] ISO_OVR rw — Isolation Override
  [21] TX_DIS rw — Driver Disable
  [18] RXACTIVE rw — Input enable for the Pad
  [15] FORCE_DS_EN rw — Enable pad Deep Sleep controls by overriding DMSC gating
  [14] ST_EN rw — Receiver Schmitt Trigger enable
  [13:11] DEBOUNCE_SEL rw — Selects the debounce period for the pad.
  [8] WK_LVL_POL rw — Level Sensitive Wakeup Polarity
  [7] WK_LVL_EN rw — Level Sensitive Wakeup Enable
  [5:4] VGPIO_SEL rw — Virtual WKUP_GPIO instance select. 0h - Implement GPIO in GPIO_WKUP_0 instance 1h - Implement GPIO in GPIO_WKUP_1 instance
  [3:0] MUXMODE rw — Pad functional signal mux selection 0h - Mux Mode 0 1h - Mux Mode 1 2h - Mux Mode 2 3h - Mux Mode 3 4h - Mux Mode 4 5h - Mux Mode 5 6h - Mux Mode 6 7h - Mux Mode 7 Fh - Mux Mode 15
0x1E110 CTRLMMR_WKUP_PADCONFIG68 reset 0x8214007
  fields as CTRLMMR_WKUP_PADCONFIG0
0x1E114 CTRLMMR_WKUP_PADCONFIG69 reset 0x44000
  fields as CTRLMMR_WKUP_PADCONFIG0
0x1E118 CTRLMMR_WKUP_PADCONFIG70 reset 0x10264000
  fields as CTRLMMR_WKUP_PADCONFIG0
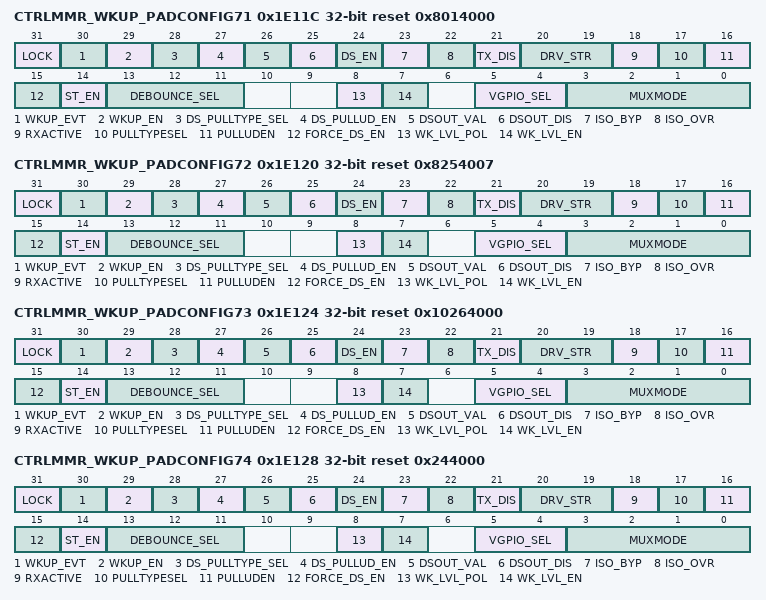
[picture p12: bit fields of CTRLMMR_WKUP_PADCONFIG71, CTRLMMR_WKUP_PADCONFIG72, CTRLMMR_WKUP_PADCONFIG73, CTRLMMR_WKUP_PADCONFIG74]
0x1E11C CTRLMMR_WKUP_PADCONFIG71 reset 0x8014000
  fields as CTRLMMR_WKUP_PADCONFIG0
0x1E120 CTRLMMR_WKUP_PADCONFIG72 reset 0x8254007
  fields as CTRLMMR_WKUP_PADCONFIG0
0x1E124 CTRLMMR_WKUP_PADCONFIG73 reset 0x10264000
  fields as CTRLMMR_WKUP_PADCONFIG0
0x1E128 CTRLMMR_WKUP_PADCONFIG74 reset 0x244000
  fields as CTRLMMR_WKUP_PADCONFIG0
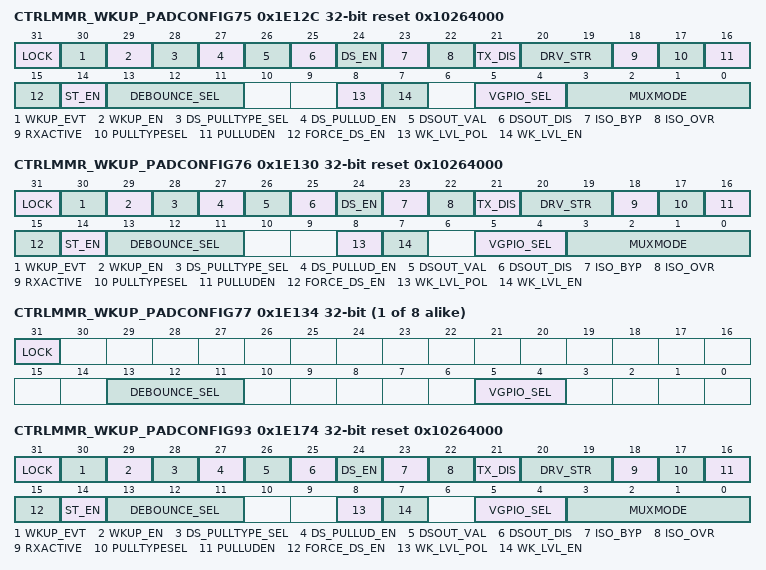
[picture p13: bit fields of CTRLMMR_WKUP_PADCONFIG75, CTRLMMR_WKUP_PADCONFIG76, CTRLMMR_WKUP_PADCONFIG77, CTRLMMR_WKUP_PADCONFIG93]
0x1E12C CTRLMMR_WKUP_PADCONFIG75 reset 0x10264000
  fields as CTRLMMR_WKUP_PADCONFIG0
0x1E130 CTRLMMR_WKUP_PADCONFIG76 reset 0x10264000
  fields as CTRLMMR_WKUP_PADCONFIG0
{0x1E000+4i} CTRLMMR_WKUP_PADCONFIG{i} (i=77..84)
  [31] LOCK rw
  [13:11] DEBOUNCE_SEL rw — Selects the debounce period for the pad.
  [5:4] VGPIO_SEL rw — Virtual WKUP_GPIO instance select. 0h - Implement GPIO in GPIO_WKUP_0 instance 1h - Implement GPIO in GPIO_WKUP_1 instance
0x1E174 CTRLMMR_WKUP_PADCONFIG93 reset 0x10264000
  fields as CTRLMMR_WKUP_PADCONFIG0
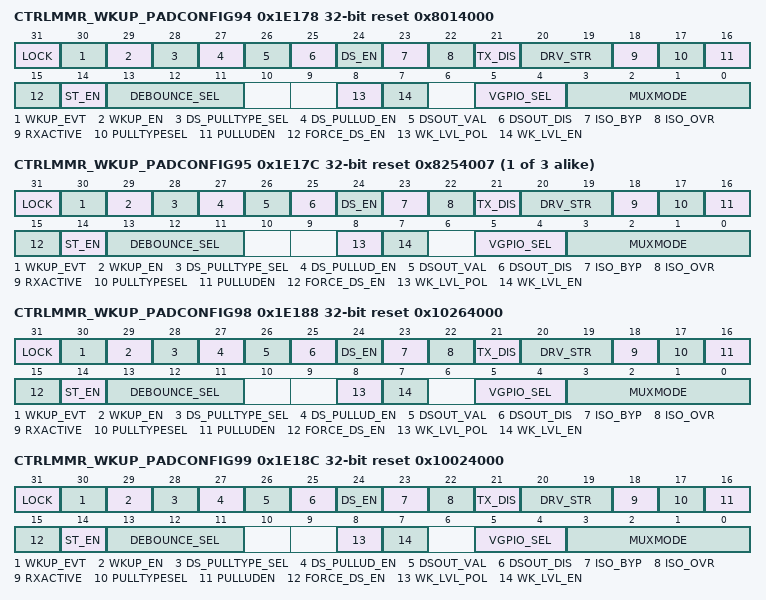
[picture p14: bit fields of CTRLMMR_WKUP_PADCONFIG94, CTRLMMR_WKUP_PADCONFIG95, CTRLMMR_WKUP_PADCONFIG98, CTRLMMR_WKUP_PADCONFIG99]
0x1E178 CTRLMMR_WKUP_PADCONFIG94 reset 0x8014000
  fields as CTRLMMR_WKUP_PADCONFIG0
{0x1E000+4i} CTRLMMR_WKUP_PADCONFIG{i} reset 0x8254007 (i=95..97)
  fields as CTRLMMR_WKUP_PADCONFIG0
0x1E188 CTRLMMR_WKUP_PADCONFIG98 reset 0x10264000
  fields as CTRLMMR_WKUP_PADCONFIG0
0x1E18C CTRLMMR_WKUP_PADCONFIG99 reset 0x10024000
  fields as CTRLMMR_WKUP_PADCONFIG0
0x1E190 CTRLMMR_WKUP_PADCONFIG100 reset 0x8010000
  fields as CTRLMMR_WKUP_PADCONFIG0
0x1F008 CTRLMMR_WKUP_LOCK7_KICK0
  [31:1] KEY rw — Write the kick0 unlock value followed by the kick1 unlock value to unlock the write-protected Partition7 registers
  [0] UNLOCKED ro — Unlock status.
0x1F00C CTRLMMR_WKUP_LOCK7_KICK1 rw
  [31:0] KEY — Write the kick1 unlock value after the kick0 unlock value to unlock the write-protected Partition7 registers
{0x1F100+4i} CTRLMMR_WKUP_P7_CLAIM{i} rw (i=0..3)
  [31:0] PROXY1_CLAIMED — Proxy1 register claim bit
